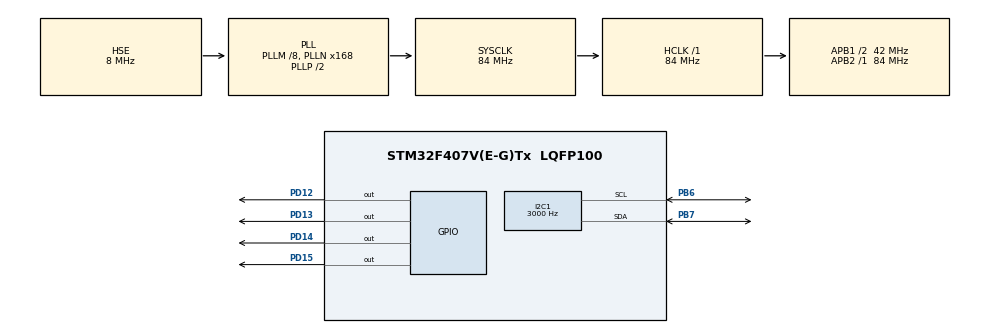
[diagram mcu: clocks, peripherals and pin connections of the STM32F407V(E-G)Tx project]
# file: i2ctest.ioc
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I2C1.ClockSpeed=3000
Mcu.Family=STM32F4
Mcu.Name=STM32F407V(E-G)Tx
Mcu.Package=LQFP100
NVIC.PriorityGroup=NVIC_PRIORITYGROUP_4
PB6.Mode=I2C
PB6.Signal=I2C1_SCL
PB7.Mode=I2C
PB7.Signal=I2C1_SDA
PD12.GPIO_ModeDefaultOutputPP=GPIO_MODE_OUTPUT_PP
PD12.GPIO_Speed=GPIO_SPEED_FREQ_VERY_HIGH
PD12.PinState=GPIO_PIN_RESET
PD12.Signal=GPIO_Output
PD13.GPIO_Speed=GPIO_SPEED_FREQ_VERY_HIGH
PD13.Signal=GPIO_Output
PD14.GPIO_Speed=GPIO_SPEED_FREQ_VERY_HIGH
PD14.Signal=GPIO_Output
PD15.GPIO_Speed=GPIO_SPEED_FREQ_VERY_HIGH
PD15.Signal=GPIO_Output
PH0-OSC_IN.Mode=HSE-External-Clock-Source
PH0-OSC_IN.Signal=RCC_OSC_IN
PH1-OSC_OUT.Mode=HSE-External-Clock-Source
PH1-OSC_OUT.Signal=RCC_OSC_OUT
ProjectManager.HeapSize=0x200
ProjectManager.StackSize=0x400
ProjectManager.TargetToolchain=SW4STM32
RCC.48MHZClocksFreq_Value=42000000
RCC.AHBFreq_Value=84000000
RCC.APB1CLKDivider=RCC_HCLK_DIV2
RCC.APB1Freq_Value=42000000
RCC.APB1TimFreq_Value=84000000
RCC.APB2Freq_Value=84000000
RCC.APB2TimFreq_Value=84000000
RCC.CortexFreq_Value=84000000
RCC.HCLKFreq_Value=84000000
RCC.HSE_VALUE=8000000
RCC.HSI_VALUE=16000000
RCC.LSE_VALUE=32768
RCC.PLLM=8
RCC.PLLN=168
RCC.PLLSourceVirtual=RCC_PLLSOURCE_HSE
RCC.SYSCLKFreq_VALUE=84000000
RCC.SYSCLKSource=RCC_SYSCLKSOURCE_PLLCLK
RCC.VCOOutputFreq_Value=168000000
VP_RTC_VS_RTC_Activate.Mode=RTC_Enabled
VP_RTC_VS_RTC_Calendar.Mode=RTC_Calendar
board=custom

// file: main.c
/* USER CODE BEGIN Header */
/**
  ******************************************************************************
  * @file           : main.c
  * @brief          : Main program body
  ******************************************************************************
  ** This notice applies to any and all portions of this file
  * that are not between comment pairs USER CODE BEGIN and
  * USER CODE END. Other portions of this file, whether
  * inserted by the user or by software development tools
  * are owned by their respective copyright owners.
  *
  * COPYRIGHT(c) 2019 STMicroelectronics
  *
  * Redistribution and use in source and binary forms, with or without modification,
  * are permitted provided that the following conditions are met:
  *   1. Redistributions of source code must retain the above copyright notice,
  *      this list of conditions and the following disclaimer.
  *   2. Redistributions in binary form must reproduce the above copyright notice,
  *      this list of conditions and the following disclaimer in the documentation
  *      and/or other materials provided with the distribution.
  *   3. Neither the name of STMicroelectronics nor the names of its contributors
  *      may be used to endorse or promote products derived from this software
  *      without specific prior written permission.
  *
  * THIS SOFTWARE IS PROVIDED BY THE COPYRIGHT HOLDERS AND CONTRIBUTORS "AS IS"
  * AND ANY EXPRESS OR IMPLIED WARRANTIES, INCLUDING, BUT NOT LIMITED TO, THE
  * IMPLIED WARRANTIES OF MERCHANTABILITY AND FITNESS FOR A PARTICULAR PURPOSE ARE
  * DISCLAIMED. IN NO EVENT SHALL THE COPYRIGHT HOLDER OR CONTRIBUTORS BE LIABLE
  * FOR ANY DIRECT, INDIRECT, INCIDENTAL, SPECIAL, EXEMPLARY, OR CONSEQUENTIAL
  * DAMAGES (INCLUDING, BUT NOT LIMITED TO, PROCUREMENT OF SUBSTITUTE GOODS OR
  * SERVICES; LOSS OF USE, DATA, OR PROFITS; OR BUSINESS INTERRUPTION) HOWEVER
  * CAUSED AND ON ANY THEORY OF LIABILITY, WHETHER IN CONTRACT, STRICT LIABILITY,
  * OR TORT (INCLUDING NEGLIGENCE OR OTHERWISE) ARISING IN ANY WAY OUT OF THE USE
  * OF THIS SOFTWARE, EVEN IF ADVISED OF THE POSSIBILITY OF SUCH DAMAGE.
  *
  ******************************************************************************
  */
/* USER CODE END Header */

#include "main.h"

/* USER CODE BEGIN Includes */
#include "ssd1306_tests.h"
#include "ssd1306.h"
#include "rtc_mon_1.h"
/* USER CODE END Includes */
int x;

I2C_HandleTypeDef hi2c1;

RTC_HandleTypeDef hrtc;

/* USER CODE BEGIN PV */
RTC_TimeTypeDef sTime;
RTC_DateTypeDef sDate;

/* USER CODE END PV */

void SystemClock_Config(void);
static void MX_GPIO_Init(void);
static void MX_I2C1_Init(void);
static void MX_RTC_Init(void);

/* USER CODE BEGIN 0 */
void init() {
	ssd1306_Init();
    ssd1306_Fill(White);
    // Flush buffer to screen
    ssd1306_UpdateScreen();
}
void func3()
{
	  void (*jumpaddr)(GPIO_TypeDef *GPIOx , uint16_t GPIO_Pin)=&HAL_GPIO_TogglePin;//&HAL_GPIO_TogglePin
			  jumpaddr(GPIOD, GPIO_PIN_12);
}
/* USER CODE END 0 */

int main(void)
{

  /* MCU Configuration--------------------------------------------------------*/

  /* Reset of all peripherals, Initializes the Flash interface and the Systick. */
  HAL_Init();

  /* Configure the system clock */
  SystemClock_Config();

  /* USER CODE BEGIN SysInit */
  __HAL_RCC_PWR_CLK_ENABLE();
  void HAL_PWR_EnableBkUpAccess();
  __HAL_RCC_RTC_CONFIG(RCC_RTCCLKSOURCE_LSI);
  __HAL_RCC_RTC_ENABLE();

  /* USER CODE END SysInit */

  /* Initialize all configured peripherals */
  MX_GPIO_Init();
  MX_I2C1_Init();
  MX_RTC_Init();
  /* USER CODE BEGIN 2 */
  init();

  func3();
  /* USER CODE END 2 */

  /* Infinite loop */
  /* USER CODE BEGIN WHILE */
  while (1)
  {
	//  HAL_PWR_EnterSTOPMode(PWR_LOWPOWERREGULATOR_ON,PWR_STOPENTRY_WFI);
	  HAL_GPIO_TogglePin(GPIOD, GPIO_PIN_12);
	  HAL_RTC_GetTime(&hrtc,&sTime,RTC_FORMAT_BIN);
	  HAL_RTC_GetDate(&hrtc, &sDate, RTC_FORMAT_BIN);
	  RTC_Mon(&sTime);

	  	HAL_Delay(100);

    /* USER CODE END WHILE */

    /* USER CODE BEGIN 3 */
	  	x=&hrtc.Instance;
  }
  /* USER CODE END 3 */
}

void SystemClock_Config(void)
{
  RCC_OscInitTypeDef RCC_OscInitStruct = {0};
  RCC_ClkInitTypeDef RCC_ClkInitStruct = {0};
  RCC_PeriphCLKInitTypeDef PeriphClkInitStruct = {0};

  /**Configure the main internal regulator output voltage
  */
  __HAL_RCC_PWR_CLK_ENABLE();
  __HAL_PWR_VOLTAGESCALING_CONFIG(PWR_REGULATOR_VOLTAGE_SCALE1);
  /**Initializes the CPU, AHB and APB busses clocks
  */
  RCC_OscInitStruct.OscillatorType = RCC_OSCILLATORTYPE_LSI|RCC_OSCILLATORTYPE_HSE;
  RCC_OscInitStruct.HSEState = RCC_HSE_BYPASS;
  RCC_OscInitStruct.LSIState = RCC_LSI_ON;
  RCC_OscInitStruct.PLL.PLLState = RCC_PLL_ON;
  RCC_OscInitStruct.PLL.PLLSource = RCC_PLLSOURCE_HSE;
  RCC_OscInitStruct.PLL.PLLM = 8;
  RCC_OscInitStruct.PLL.PLLN = 168;
  RCC_OscInitStruct.PLL.PLLP = RCC_PLLP_DIV2;
  RCC_OscInitStruct.PLL.PLLQ = 4;
  if (HAL_RCC_OscConfig(&RCC_OscInitStruct) != HAL_OK)
  {
    Error_Handler();
  }
  /**Initializes the CPU, AHB and APB busses clocks
  */
  RCC_ClkInitStruct.ClockType = RCC_CLOCKTYPE_HCLK|RCC_CLOCKTYPE_SYSCLK
                              |RCC_CLOCKTYPE_PCLK1|RCC_CLOCKTYPE_PCLK2;
  RCC_ClkInitStruct.SYSCLKSource = RCC_SYSCLKSOURCE_PLLCLK;
  RCC_ClkInitStruct.AHBCLKDivider = RCC_SYSCLK_DIV1;
  RCC_ClkInitStruct.APB1CLKDivider = RCC_HCLK_DIV2;
  RCC_ClkInitStruct.APB2CLKDivider = RCC_HCLK_DIV1;

  if (HAL_RCC_ClockConfig(&RCC_ClkInitStruct, FLASH_LATENCY_2) != HAL_OK)
  {
    Error_Handler();
  }
  PeriphClkInitStruct.PeriphClockSelection = RCC_PERIPHCLK_RTC;
  PeriphClkInitStruct.RTCClockSelection = RCC_RTCCLKSOURCE_LSI;
  if (HAL_RCCEx_PeriphCLKConfig(&PeriphClkInitStruct) != HAL_OK)
  {
    Error_Handler();
  }
}

static void MX_I2C1_Init(void)
{

  hi2c1.Instance = I2C1;
  hi2c1.Init.ClockSpeed = 100000;
  hi2c1.Init.DutyCycle = I2C_DUTYCYCLE_2;
  hi2c1.Init.OwnAddress1 = 0;
  hi2c1.Init.AddressingMode = I2C_ADDRESSINGMODE_7BIT;
  hi2c1.Init.DualAddressMode = I2C_DUALADDRESS_DISABLE;
  hi2c1.Init.OwnAddress2 = 0;
  hi2c1.Init.GeneralCallMode = I2C_GENERALCALL_DISABLE;
  hi2c1.Init.NoStretchMode = I2C_NOSTRETCH_DISABLE;
  if (HAL_I2C_Init(&hi2c1) != HAL_OK)
  {
    Error_Handler();
  }

}

static void MX_RTC_Init(void)
{

  RTC_TimeTypeDef sTime = {0};
  RTC_DateTypeDef sDate = {0};
  RTC_AlarmTypeDef sAlarm = {0};

  /**Initialize RTC Only
  */
  hrtc.Instance = RTC;
  hrtc.Init.HourFormat = RTC_HOURFORMAT_24;
  hrtc.Init.AsynchPrediv = 127;
  hrtc.Init.SynchPrediv = 255;
  hrtc.Init.OutPut = RTC_OUTPUT_DISABLE;
  hrtc.Init.OutPutPolarity = RTC_OUTPUT_POLARITY_HIGH;
  hrtc.Init.OutPutType = RTC_OUTPUT_TYPE_OPENDRAIN;
  if (HAL_RTC_Init(&hrtc) != HAL_OK)
  {
    Error_Handler();
  }

  /**Initialize RTC and set the Time and Date
  */
  sTime.Hours = 0x23;
  sTime.Minutes = 0x59;
  sTime.Seconds = 0x59;
  sTime.DayLightSaving = RTC_DAYLIGHTSAVING_NONE;
  sTime.StoreOperation = RTC_STOREOPERATION_RESET;
  if (HAL_RTC_SetTime(&hrtc, &sTime, RTC_FORMAT_BCD) != HAL_OK)
  {
    Error_Handler();
  }
  sDate.WeekDay = RTC_WEEKDAY_MONDAY;
  sDate.Month = RTC_MONTH_JANUARY;
  sDate.Date = 0x1;
  sDate.Year = 0x19;

  if (HAL_RTC_SetDate(&hrtc, &sDate, RTC_FORMAT_BCD) != HAL_OK)
  {
    Error_Handler();
  }
  /**Enable the Alarm A
  */
  sAlarm.AlarmTime.Hours = 0x0;
  sAlarm.AlarmTime.Minutes = 0x0;
  sAlarm.AlarmTime.Seconds = 0x5;
  sAlarm.AlarmTime.SubSeconds = 0x0;
  sAlarm.AlarmTime.DayLightSaving = RTC_DAYLIGHTSAVING_NONE;
  sAlarm.AlarmTime.StoreOperation = RTC_STOREOPERATION_RESET;
  sAlarm.AlarmMask = RTC_ALARMMASK_NONE;
  sAlarm.AlarmSubSecondMask = RTC_ALARMSUBSECONDMASK_ALL;
  sAlarm.AlarmDateWeekDaySel = RTC_ALARMDATEWEEKDAYSEL_DATE;
  sAlarm.AlarmDateWeekDay = 0x1;
  sAlarm.Alarm = RTC_ALARM_A;
  if (HAL_RTC_SetAlarm(&hrtc, &sAlarm, RTC_FORMAT_BCD) != HAL_OK)
  {
    Error_Handler();
  }
  /**Enable the Alarm B
  */
  sAlarm.AlarmTime.Seconds = 0x0;
  sAlarm.AlarmDateWeekDay = 0x1;
  sAlarm.Alarm = RTC_ALARM_B;
  if (HAL_RTC_SetAlarm(&hrtc, &sAlarm, RTC_FORMAT_BCD) != HAL_OK)
  {
    Error_Handler();
  }

}

static void MX_GPIO_Init(void)
{
  GPIO_InitTypeDef GPIO_InitStruct = {0};

  /* GPIO Ports Clock Enable */
  __HAL_RCC_GPIOC_CLK_ENABLE();
  __HAL_RCC_GPIOH_CLK_ENABLE();
  __HAL_RCC_GPIOA_CLK_ENABLE();
  __HAL_RCC_GPIOD_CLK_ENABLE();
  __HAL_RCC_GPIOB_CLK_ENABLE();

  /*Configure GPIO pin Output Level */
  HAL_GPIO_WritePin(GPIOD, GPIO_PIN_12|GPIO_PIN_13|GPIO_PIN_14|GPIO_PIN_15, GPIO_PIN_RESET);

  /*Configure GPIO pin : PA0 */
  GPIO_InitStruct.Pin = GPIO_PIN_0;
  GPIO_InitStruct.Mode = GPIO_MODE_IT_RISING;
  GPIO_InitStruct.Pull = GPIO_NOPULL;
  HAL_GPIO_Init(GPIOA, &GPIO_InitStruct);

  /*Configure GPIO pins : PD12 PD13 PD14 PD15 */
  GPIO_InitStruct.Pin = GPIO_PIN_12|GPIO_PIN_13|GPIO_PIN_14|GPIO_PIN_15;
  GPIO_InitStruct.Mode = GPIO_MODE_OUTPUT_PP;
  GPIO_InitStruct.Pull = GPIO_NOPULL;
  GPIO_InitStruct.Speed = GPIO_SPEED_FREQ_VERY_HIGH;
  HAL_GPIO_Init(GPIOD, &GPIO_InitStruct);

  /* EXTI interrupt init*/
  HAL_NVIC_SetPriority(EXTI0_IRQn, 0, 0);
  HAL_NVIC_EnableIRQ(EXTI0_IRQn);

}

/* USER CODE BEGIN 4 */

void HAL_GPIO_EXTI_Callback(uint16_t GPIO_Pin)
	{
		if(GPIO_Pin==GPIO_PIN_0)
			{
				HAL_GPIO_TogglePin(GPIOD, GPIO_PIN_14);
				  sTime.Hours = 0x13;
				  sTime.Minutes = 0x44;
				  sTime.Seconds = 0x59;
				  HAL_RTC_SetTime(&hrtc, &sTime, RTC_FORMAT_BCD);
			}
	}

/* USER CODE END 4 */

void Error_Handler(void)
{
}

/************************ (C) COPYRIGHT STMicroelectronics *****END OF FILE****/
